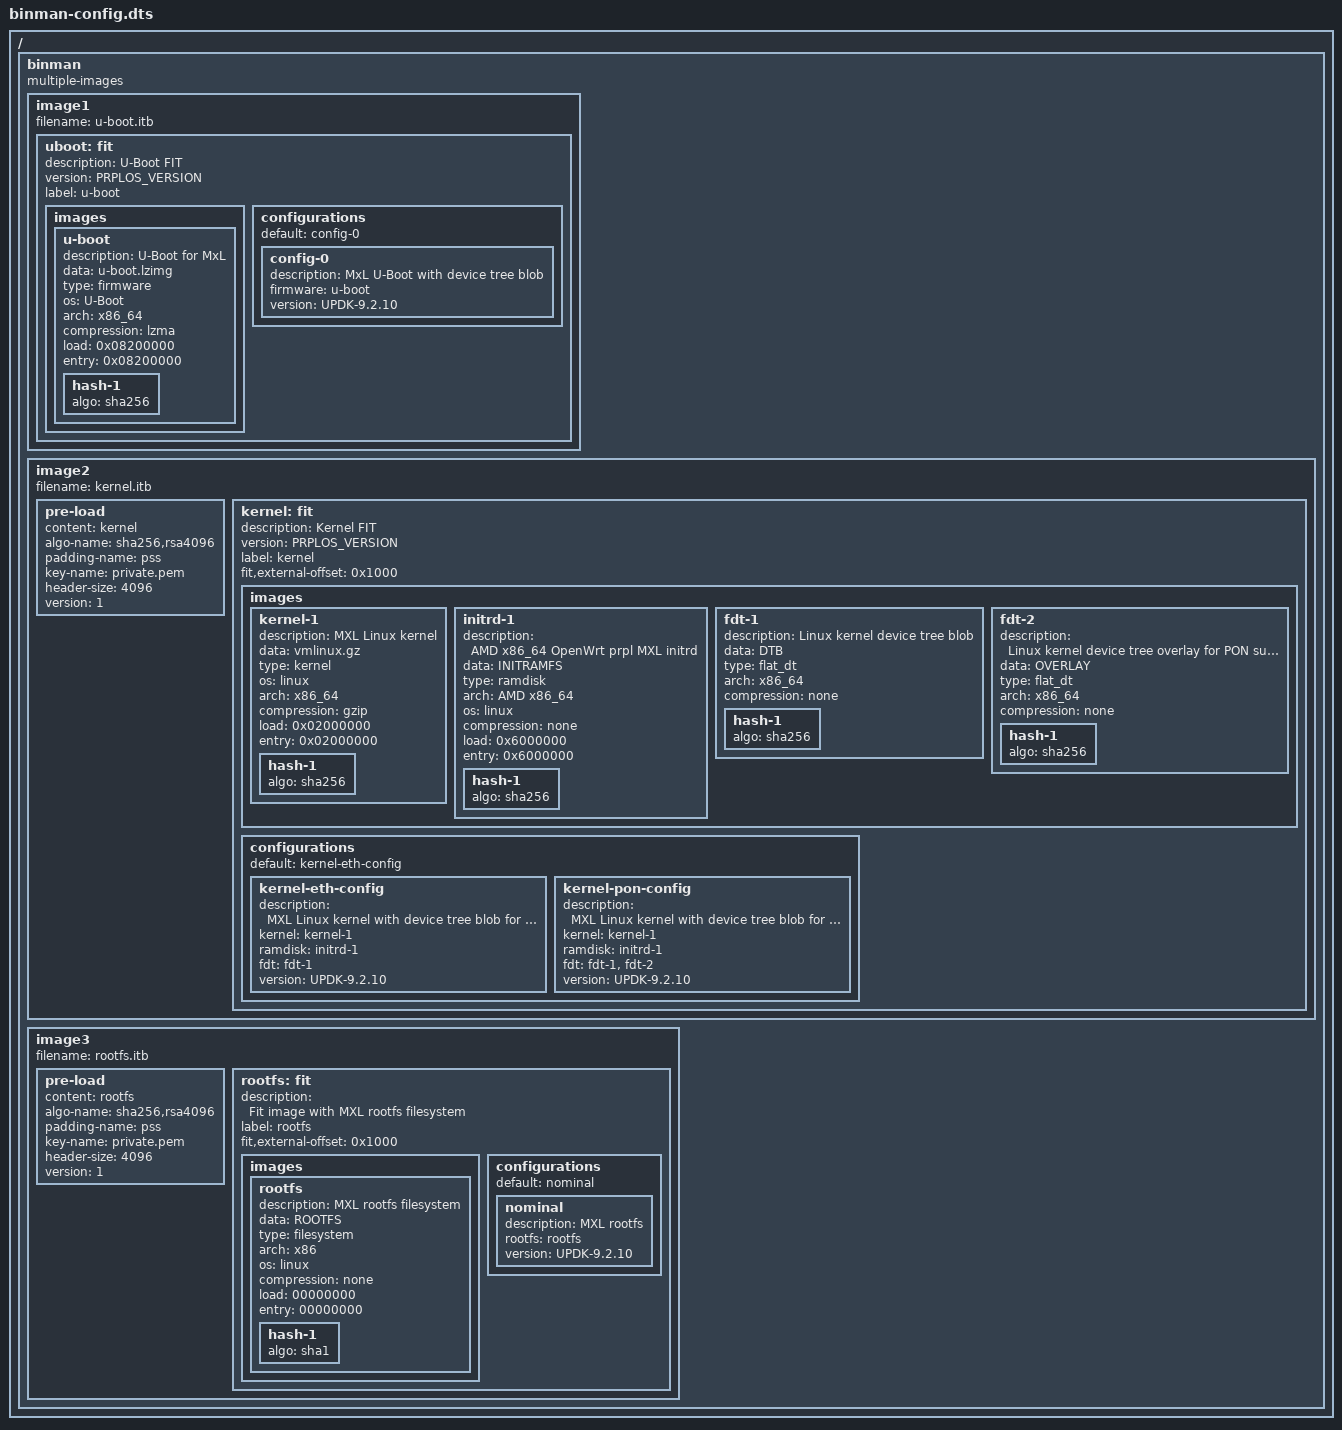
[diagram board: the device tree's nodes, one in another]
/*
 * Binman configuration for non-secure boot image generation
 *
 * Defines the layout for generating FIT images:
 *   image1: u-boot.itb  - U-Boot firmware (LZMA compressed)
 *   image2: kernel.itb  - Linux kernel, initrd, and device tree blobs
 *                         with pre-load signature (sha256,rsa4096/pss)
 *   image3: rootfs.itb  - Root filesystem
 *                         with pre-load signature (sha256,rsa4096/pss)
 */

/dts-v1/;

/ {
	binman {
		multiple-images;
		image1 {
			filename = "u-boot.itb";
			uboot: fit {
				description = "U-Boot FIT";
				version = PRPLOS_VERSION;
				label = "u-boot";
				images {
					u-boot {
						description = "U-Boot for MxL";
						data = /incbin/("u-boot.lzimg");
						type = "firmware";
						os = "U-Boot";
						arch = "x86_64";
						compression = "lzma";
						load = <0x08200000>;
						entry = <0x08200000>;
						hash-1 {
							algo = "sha256";
						};
					};
				};
				configurations {
					default = "config-0";
					config-0 {
						description = "MxL U-Boot with device tree blob";
						firmware = "u-boot";
						version = "UPDK-9.2.10";
					};
				};
			};
		};
		image2 {
			filename = "kernel.itb";
			pre-load {
				content = <&kernel>;
				algo-name = "sha256,rsa4096";
				padding-name = "pss";
				key-name = "private.pem";
				header-size = <4096>;
				version = <1>;
			};
			kernel: fit {
				description = "Kernel FIT";
				version = PRPLOS_VERSION;
				label = "kernel";
				fit,external-offset = <0x1000>;
				images {
					kernel-1 {
						description = "MXL Linux kernel";
						data = /incbin/("vmlinux.gz");
						type = "kernel";
						os = "linux";
						arch = "x86_64";
						compression = "gzip";
						load = <0x02000000>;
						entry = <0x02000000>;
						hash-1 {
							algo = "sha256";
						};
					};
					initrd-1 {
						description = "AMD x86_64 OpenWrt prpl MXL initrd";
						data = /incbin/("INITRAMFS");
						type = "ramdisk";
						arch = "AMD x86_64";
						os = "linux";
						compression = "none";
						load = <0x6000000>;
						entry = <0x6000000>;
						hash-1 {
							algo = "sha256";
						};
					};
					fdt-1 {
						description = "Linux kernel device tree blob";
						data = /incbin/("DTB");
						type = "flat_dt";
						arch = "x86_64";
						compression = "none";
						hash-1 {
							algo = "sha256";
						};
					};
					fdt-2 {
						description = "Linux kernel device tree overlay for PON support";
						data = /incbin/("OVERLAY");
						type = "flat_dt";
						arch = "x86_64";
						compression = "none";
						hash-1 {
							algo = "sha256";
						};
					};
				};
				configurations {
					default = "kernel-eth-config";
					kernel-eth-config {
						description = "MXL Linux kernel with device tree blob for Ethernet";
						kernel = "kernel-1";
						ramdisk = "initrd-1";
						fdt = "fdt-1";
						version = "UPDK-9.2.10";
					};
					kernel-pon-config {
						description = "MXL Linux kernel with device tree blob for PON";
						kernel = "kernel-1";
						ramdisk = "initrd-1";
						fdt = "fdt-1", "fdt-2";
						version = "UPDK-9.2.10";
					};
				};
			};
		};
		image3 {
			filename = "rootfs.itb";
			pre-load {
					content = <&rootfs>;
					algo-name = "sha256,rsa4096";
					padding-name = "pss";
					key-name = "private.pem";
					header-size = <4096>;
					version = <1>;
			};
			rootfs: fit {
				description = "Fit image with MXL rootfs filesystem";
				label = "rootfs";
				fit,external-offset = <0x1000>;
				images {
					rootfs {
						description = "MXL rootfs filesystem";
						data = /incbin/("ROOTFS");
						type = "filesystem";
						arch = "x86";
						os = "linux";
						compression = "none";
						load = <00000000>;
						entry = <00000000>;
						hash-1 {
							algo = "sha1";
						};
					};
				};
				configurations {
					default = "nominal";
					nominal {
						description = "MXL rootfs";
						rootfs = "rootfs";
						version = "UPDK-9.2.10";
					};
				};
			};
		};
	};
};
